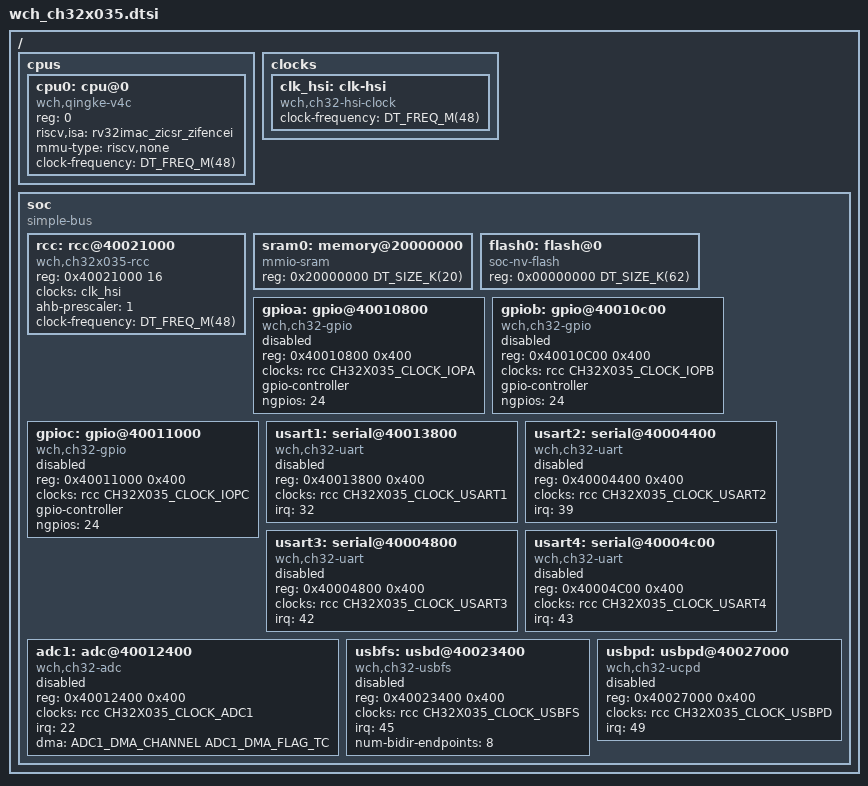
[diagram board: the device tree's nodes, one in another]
/*
 * Copyright (c) 2025 TiaC Systems
 * Copyright (c) 2024 Matthew Tran
 * SPDX-License-Identifier: Apache-2.0
 */

#include <mem.h>
#include <freq.h>

#include <zephyr/dt-bindings/adc/ch32x035-adc.h>
#include <zephyr/dt-bindings/clock/ch32x035-clocks.h>

/ {
	#address-cells = <1>;
	#size-cells = <1>;

	cpus {
		#address-cells = <1>;
		#size-cells = <0>;

		cpu0: cpu@0 {
			device_type = "cpu";
			compatible = "wch,qingke-v4c", "riscv";
			reg = <0>;
			riscv,isa = "rv32imac_zicsr_zifencei";
			mmu-type = "riscv,none";
			clock-frequency = <DT_FREQ_M(48)>;
		};
	};

	clocks {
		clk_hsi: clk-hsi {
			compatible = "wch,ch32-hsi-clock";
			#clock-cells = <0>;
			clock-frequency = <DT_FREQ_M(48)>;
			status = "okay";
		};
	};

	soc {
		#address-cells = <1>;
		#size-cells = <1>;
		compatible = "simple-bus";
		ranges;

		// TODO interrupt controller driver for pfic
//		pfic: interrupt-controller@e000e000 {
//			compatible = "wch,qingke-pfic";
//			reg = <0xe000e000 0x10>;
//			interrupt-controller;
//			#interrupt-cells = <1>;
//			#address-cells = <0>;
//			status = "okay";
//		};

		// TODO timer driver for systick
//		systick: systimer@e000f000 {
//			compatible = "wch,qingke-systick";
//			reg = <0xe000f000 0x10>;
//			interrupt-parent = <&pfic>;
//			interrupts = <12>;
//			status = "okay";
//		};

		rcc: rcc@40021000 {
			compatible = "wch,ch32x035-rcc", "wch,ch32-rcc";
			reg = <0x40021000 16>;
			#clock-cells = <1>;
			clocks = <&clk_hsi>;
			ahb-prescaler = <1>;
			clock-frequency = <DT_FREQ_M(48)>;
		};

		sram0: memory@20000000 {
			compatible = "mmio-sram";
			reg = <0x20000000 DT_SIZE_K(20)>;
		};

		// TODO flash controller driver for flash interface
//		flash: flash-controller@40022000 {
//			compatible = "wch,ch32-flash-controller";
//			reg = <0x40022000 0x400>;
//			#address-cells = <1>;
//			#size-cells = <1>;
//
//			flash0: flash@0 {
//				compatible = "soc-nv-flash";
//				reg = <0x08000000 DT_SIZE_K(62)>;
//			};
//		};
		flash0: flash@0 {
			compatible = "soc-nv-flash";
			reg = <0x00000000 DT_SIZE_K(62)>;
		};

		// TODO pinctrl driver for gpio and remap
//		pinctrl: pin-controller@40010000 {
//			compatible = "wch,ch32-afio";
//			reg = <0x40010000 16>;
//			clocks = <&rcc CH32X035_CLOCK_AFIO>;
//			#address-cells = <1>;
//			#size-cells = <1>;
//
//			gpioa: gpio@40010800 {
//				compatible = "wch,ch32-gpio";
//				reg = <0x40010800 0x20>;
//				clocks = <&rcc CH32X035_CLOCK_IOPA>;
//				gpio-controller;
//				#gpio-cells = <2>;
//				ngpios = <24>;
//				status = "disabled";
//			};
//
//			gpiob: gpio@40010C00 {
//				compatible = "wch,ch32-gpio";
//				reg = <0x40010C00 0x20>;
//				clocks = <&rcc CH32X035_CLOCK_IOPB>;
//				gpio-controller;
//				#gpio-cells = <2>;
//				ngpios = <24>;
//				status = "disabled";
//			};
//
//			gpioc: gpio@40011000 {
//				compatible = "wch,ch32-gpio";
//				reg = <0x40011000 0x20>;
//				clocks = <&rcc CH32X035_CLOCK_IOPC>;
//				gpio-controller;
//				#gpio-cells = <2>;
//				ngpios = <24>;
//				status = "disabled";
//			};
//		};
		gpioa: gpio@40010800 {
			compatible = "wch,ch32-gpio";
			reg = <0x40010800 0x400>;
			clocks = <&rcc CH32X035_CLOCK_IOPA>;
			gpio-controller;
			#gpio-cells = <2>;
			ngpios = <24>;
			status = "disabled";
		};

		gpiob: gpio@40010c00 {
			compatible = "wch,ch32-gpio";
			reg = <0x40010C00 0x400>;
			clocks = <&rcc CH32X035_CLOCK_IOPB>;
			gpio-controller;
			#gpio-cells = <2>;
			ngpios = <24>;
			status = "disabled";
		};

		gpioc: gpio@40011000 {
			compatible = "wch,ch32-gpio";
			reg = <0x40011000 0x400>;
			clocks = <&rcc CH32X035_CLOCK_IOPC>;
			gpio-controller;
			#gpio-cells = <2>;
			ngpios = <24>;
			status = "disabled";
		};

		usart1: serial@40013800 {
			compatible = "wch,ch32-uart";
			reg = <0x40013800 0x400>;
			clocks = <&rcc CH32X035_CLOCK_USART1>;
			irq = <32>; // USART1_IRQn
//			interrupt-parent = <&pfic>;
//			interrupts = <32>;
			status = "disabled";
		};

		usart2: serial@40004400 {
			compatible = "wch,ch32-uart";
			reg = <0x40004400 0x400>;
			clocks = <&rcc CH32X035_CLOCK_USART2>;
			irq = <39>; // USART2_IRQn
//			interrupt-parent = <&pfic>;
//			interrupts = <39>;
			status = "disabled";
		};

		usart3: serial@40004800 {
			compatible = "wch,ch32-uart";
			reg = <0x40004800 0x400>;
			clocks = <&rcc CH32X035_CLOCK_USART3>;
			irq = <42>; // USART3_IRQn
//			interrupt-parent = <&pfic>;
//			interrupts = <42>;
			status = "disabled";
		};

		usart4: serial@40004c00 {
			compatible = "wch,ch32-uart";
			reg = <0x40004C00 0x400>;
			clocks = <&rcc CH32X035_CLOCK_USART4>;
			irq = <43>; // USART4_IRQn
//			interrupt-parent = <&pfic>;
//			interrupts = <43>;
			status = "disabled";
		};

		adc1: adc@40012400 {
			compatible = "wch,ch32-adc";
			reg = <0x40012400 0x400>;
			clocks = <&rcc CH32X035_CLOCK_ADC1>;
			irq = <22>; // DMA1_Channel1_IRQn
//			interrupt-parent = <&pfic>;
//			interrupts = <22>;
			dma = <ADC1_DMA_CHANNEL ADC1_DMA_FLAG_TC>;
			#address-cells = <1>;
			#size-cells = <0>;
			#io-channel-cells = <1>;
			status = "disabled";
		};

		usbfs: usbd@40023400 {
			compatible = "wch,ch32-usbfs";
			reg = <0x40023400 0x400>;
			clocks = <&rcc CH32X035_CLOCK_USBFS>;
			irq = <45>; // USBFS_IRQn
//			interrupt-parent = <&pfic>;
//			interrupts = <45>;
			num-bidir-endpoints = <8>;
			status = "disabled";
		};

		usbpd: usbpd@40027000 {
			compatible = "wch,ch32-ucpd";
			reg = <0x40027000 0x400>;
			clocks = <&rcc CH32X035_CLOCK_USBPD>;
			irq = <49>; // USBPD_IRQn
//			interrupt-parent = <&pfic>;
//			interrupts = <49>;
			status = "disabled";
		};
	};
};
